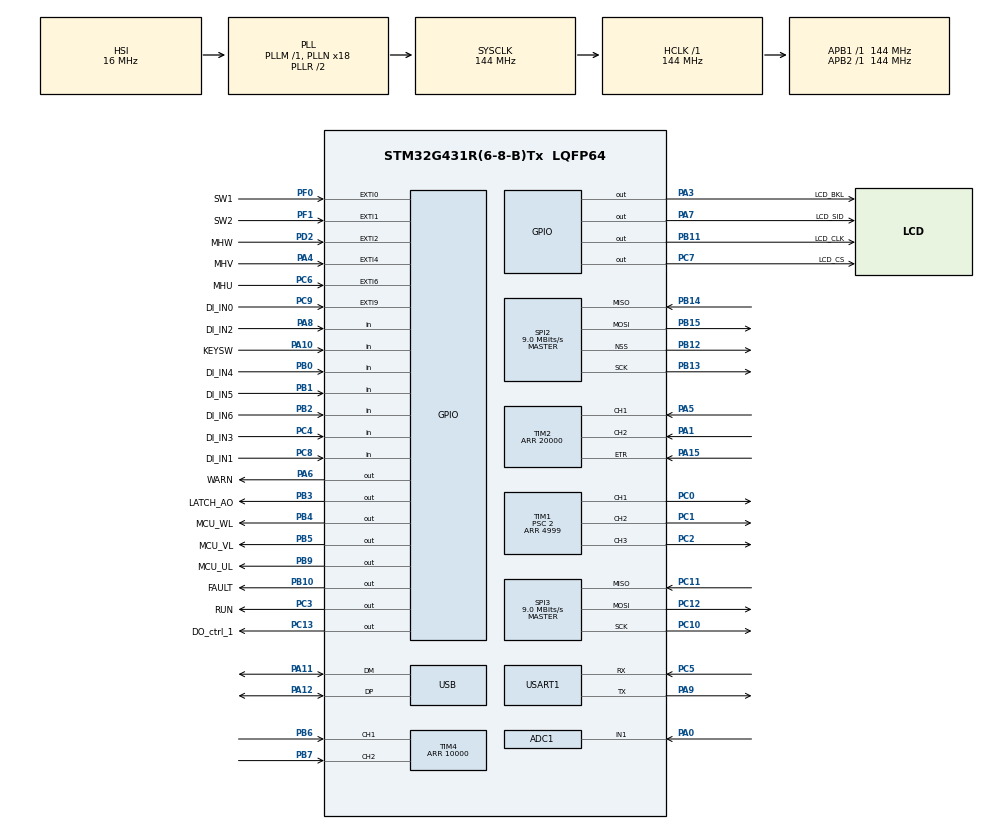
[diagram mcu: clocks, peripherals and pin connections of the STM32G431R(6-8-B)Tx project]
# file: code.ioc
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ADC1.Channel-1\#ChannelRegularConversion=ADC_CHANNEL_1
ADC1.ContinuousConvMode=ENABLE
ADC1.DMAContinuousRequests=ENABLE
ADC1.NbrOfConversionFlag=1
ADC1.OffsetNumber-1\#ChannelRegularConversion=ADC_OFFSET_NONE
ADC1.Rank-1\#ChannelRegularConversion=1
ADC1.SamplingTime-1\#ChannelRegularConversion=ADC_SAMPLETIME_247CYCLES_5
ADC1.master=1
Dma.ADC1.0.Direction=DMA_PERIPH_TO_MEMORY
Dma.ADC1.0.EventEnable=DISABLE
Dma.ADC1.0.Instance=DMA1_Channel1
Dma.ADC1.0.MemDataAlignment=DMA_MDATAALIGN_HALFWORD
Dma.ADC1.0.MemInc=DMA_MINC_ENABLE
Dma.ADC1.0.Mode=DMA_NORMAL
Dma.ADC1.0.PeriphDataAlignment=DMA_PDATAALIGN_HALFWORD
Dma.ADC1.0.PeriphInc=DMA_PINC_DISABLE
Dma.ADC1.0.Polarity=HAL_DMAMUX_REQ_GEN_RISING
Dma.ADC1.0.Priority=DMA_PRIORITY_LOW
Dma.ADC1.0.RequestNumber=1
Dma.ADC1.0.SignalID=NONE
Dma.ADC1.0.SyncEnable=DISABLE
Dma.ADC1.0.SyncPolarity=HAL_DMAMUX_SYNC_NO_EVENT
Dma.ADC1.0.SyncRequestNumber=1
Dma.ADC1.0.SyncSignalID=NONE
Dma.Request0=ADC1
Dma.Request1=USART1_RX
Dma.USART1_RX.1.Direction=DMA_PERIPH_TO_MEMORY
Dma.USART1_RX.1.EventEnable=DISABLE
Dma.USART1_RX.1.Instance=DMA1_Channel2
Dma.USART1_RX.1.MemDataAlignment=DMA_MDATAALIGN_BYTE
Dma.USART1_RX.1.MemInc=DMA_MINC_ENABLE
Dma.USART1_RX.1.Mode=DMA_NORMAL
Dma.USART1_RX.1.PeriphDataAlignment=DMA_PDATAALIGN_BYTE
Dma.USART1_RX.1.PeriphInc=DMA_PINC_DISABLE
Dma.USART1_RX.1.Polarity=HAL_DMAMUX_REQ_GEN_RISING
Dma.USART1_RX.1.Priority=DMA_PRIORITY_LOW
Dma.USART1_RX.1.RequestNumber=1
Dma.USART1_RX.1.SignalID=NONE
Dma.USART1_RX.1.SyncEnable=DISABLE
Dma.USART1_RX.1.SyncPolarity=HAL_DMAMUX_SYNC_NO_EVENT
Dma.USART1_RX.1.SyncRequestNumber=1
Dma.USART1_RX.1.SyncSignalID=NONE
Mcu.Family=STM32G4
Mcu.Name=STM32G431R(6-8-B)Tx
Mcu.Package=LQFP64
NVIC.DMA1_Channel1_IRQn=true\:0\:0\:false\:false\:true\:false\:true\:true
NVIC.DMA1_Channel2_IRQn=true\:0\:0\:false\:false\:true\:false\:true\:true
NVIC.EXTI2_IRQn=true\:0\:0\:false\:false\:true\:true\:true\:true
NVIC.EXTI4_IRQn=true\:0\:0\:false\:false\:true\:true\:true\:true
NVIC.EXTI9_5_IRQn=true\:0\:0\:false\:false\:true\:true\:true\:true
NVIC.PriorityGroup=NVIC_PRIORITYGROUP_4
NVIC.TIM2_IRQn=true\:0\:0\:false\:false\:true\:true\:true\:true
NVIC.TIM4_IRQn=true\:0\:0\:false\:false\:true\:true\:true\:true
NVIC.TIM6_DAC_IRQn=true\:10\:0\:true\:false\:true\:true\:true\:true
NVIC.USART1_IRQn=true\:0\:0\:false\:false\:true\:true\:true\:true
PA0.Mode=IN1-Single-Ended
PA0.Signal=ADC1_IN1
PA1.Signal=S_TIM2_CH2
PA10.GPIO_Label=KEYSW
PA10.Signal=GPIO_Input
PA11.Mode=Device
PA11.Signal=USB_DM
PA12.Mode=Device
PA12.Signal=USB_DP
PA13.Mode=Serial_Wire
PA13.Signal=SYS_JTMS-SWDIO
PA14.Mode=Serial_Wire
PA14.Signal=SYS_JTCK-SWCLK
PA15.Signal=S_TIM2_ETR
PA2.Signal=ADC1_IN3
PA3.GPIO_Label=LCD_BKL
PA3.GPIO_PuPd=GPIO_PULLDOWN
PA3.Signal=GPIO_Output
PA4.GPIO_Label=MHV
PA4.GPIO_ModeDefaultEXTI=GPIO_MODE_IT_RISING_FALLING
PA4.GPIO_PuPd=GPIO_PULLUP
PA4.Signal=GPXTI4
PA5.Signal=S_TIM2_CH1
PA6.GPIO_Label=WARN
PA6.GPIO_PuPd=GPIO_PULLDOWN
PA6.Signal=GPIO_Output
PA7.GPIO_Label=LCD_SID
PA7.GPIO_PuPd=GPIO_PULLUP
PA7.Signal=GPIO_Output
PA8.GPIO_Label=DI_IN2
PA8.Signal=GPIO_Input
PA9.Mode=Asynchronous
PA9.Signal=USART1_TX
PB0.GPIO_Label=DI_IN4
PB0.Signal=GPIO_Input
PB1.GPIO_Label=DI_IN5
PB1.Signal=GPIO_Input
PB10.GPIO_Label=FAULT
PB10.GPIO_PuPd=GPIO_PULLDOWN
PB10.Signal=GPIO_Output
PB11.GPIO_Label=LCD_CLK
PB11.GPIO_PuPd=GPIO_PULLUP
PB11.Signal=GPIO_Output
PB12.Mode=NSS_Signal_Hard_Output
PB12.Signal=SPI2_NSS
PB13.Mode=Full_Duplex_Master
PB13.Signal=SPI2_SCK
PB14.Mode=Full_Duplex_Master
PB14.Signal=SPI2_MISO
PB15.Mode=Full_Duplex_Master
PB15.Signal=SPI2_MOSI
PB2.GPIO_Label=DI_IN6
PB2.Signal=GPIO_Input
PB3.GPIO_Label=LATCH_AO
PB3.Signal=GPIO_Output
PB4.GPIO_Label=MCU_WL
PB4.GPIO_PuPd=GPIO_PULLDOWN
PB4.GPIO_Speed=GPIO_SPEED_FREQ_MEDIUM
PB4.Signal=GPIO_Output
PB5.GPIO_Label=MCU_VL
PB5.GPIO_PuPd=GPIO_PULLDOWN
PB5.GPIO_Speed=GPIO_SPEED_FREQ_MEDIUM
PB5.Signal=GPIO_Output
PB6.Signal=S_TIM4_CH1
PB7.Signal=S_TIM4_CH2
PB9.GPIO_Label=MCU_UL
PB9.GPIO_PuPd=GPIO_PULLDOWN
PB9.GPIO_Speed=GPIO_SPEED_FREQ_MEDIUM
PB9.Signal=GPIO_Output
PC0.Signal=S_TIM1_CH1
PC1.Signal=S_TIM1_CH2
PC10.Mode=Full_Duplex_Master
PC10.Signal=SPI3_SCK
PC11.Mode=Full_Duplex_Master
PC11.Signal=SPI3_MISO
PC12.Mode=Full_Duplex_Master
PC12.Signal=SPI3_MOSI
PC13.GPIO_Label=DO_ctrl_1
PC13.GPIO_PuPd=GPIO_PULLUP
PC13.PinState=GPIO_PIN_SET
PC13.Signal=GPIO_Output
PC14-OSC32_IN.Mode=LSE-External-Oscillator
PC14-OSC32_IN.Signal=RCC_OSC32_IN
PC15-OSC32_OUT.Mode=LSE-External-Oscillator
PC15-OSC32_OUT.Signal=RCC_OSC32_OUT
PC2.Signal=S_TIM1_CH3
PC3.GPIO_Label=RUN
PC3.GPIO_PuPd=GPIO_PULLDOWN
PC3.Signal=GPIO_Output
PC4.GPIO_Label=DI_IN3
PC4.Signal=GPIO_Input
PC5.Mode=Asynchronous
PC5.Signal=USART1_RX
PC6.GPIO_Label=MHU
PC6.GPIO_ModeDefaultEXTI=GPIO_MODE_IT_RISING_FALLING
PC6.GPIO_PuPd=GPIO_PULLUP
PC6.Signal=GPXTI6
PC7.GPIO_Label=LCD_CS
PC7.GPIO_PuPd=GPIO_PULLUP
PC7.Signal=GPIO_Output
PC8.GPIO_Label=DI_IN1
PC8.Signal=GPIO_Input
PC9.GPIO_Label=DI_IN0
PC9.GPIO_ModeDefaultEXTI=GPIO_MODE_IT_FALLING
PC9.Signal=GPXTI9
PD2.GPIO_Label=MHW
PD2.GPIO_ModeDefaultEXTI=GPIO_MODE_IT_RISING_FALLING
PD2.GPIO_PuPd=GPIO_PULLUP
PD2.Signal=GPXTI2
PF0-OSC_IN.GPIO_Label=SW1
PF0-OSC_IN.GPIO_ModeDefaultEXTI=GPIO_MODE_IT_FALLING
PF0-OSC_IN.Signal=GPXTI0
PF1-OSC_OUT.GPIO_Label=SW2
PF1-OSC_OUT.GPIO_ModeDefaultEXTI=GPIO_MODE_IT_FALLING
PF1-OSC_OUT.Signal=GPXTI1
ProjectManager.HeapSize=0x200
ProjectManager.StackSize=0x400
ProjectManager.TargetToolchain=MDK-ARM V5.32
RCC.ADC12Freq_Value=144000000
RCC.AHBFreq_Value=144000000
RCC.APB1Freq_Value=144000000
RCC.APB1TimFreq_Value=144000000
RCC.APB2Freq_Value=144000000
RCC.APB2TimFreq_Value=144000000
RCC.CortexFreq_Value=144000000
RCC.EXTERNAL_CLOCK_VALUE=12288000
RCC.HCLKFreq_Value=144000000
RCC.HSE_VALUE=8000000
RCC.HSI48_VALUE=48000000
RCC.HSI_VALUE=16000000
RCC.PLLN=18
RCC.PLLQ=RCC_PLLQ_DIV6
RCC.SYSCLKFreq_VALUE=144000000
RCC.SYSCLKSource=RCC_SYSCLKSOURCE_PLLCLK
RCC.USBFreq_Value=48000000
RCC.VCOOutputFreq_Value=288000000
SH.S_TIM1_CH1.0=TIM1_CH1,PWM Generation1 CH1
SH.S_TIM1_CH2.0=TIM1_CH2,PWM Generation2 CH2
SH.S_TIM1_CH3.0=TIM1_CH3,PWM Generation3 CH3
SH.S_TIM2_CH1.0=TIM2_CH1,Encoder_Interface_w_index
SH.S_TIM2_CH2.0=TIM2_CH2,Encoder_Interface_w_index
SH.S_TIM2_ETR.0=TIM2_ETR,Encoder_Interface_w_index
SH.S_TIM4_CH1.0=TIM4_CH1,Encoder_Interface
SH.S_TIM4_CH2.0=TIM4_CH2,Encoder_Interface
SPI2.BaudRatePrescaler=SPI_BAUDRATEPRESCALER_16
SPI2.CalculateBaudRate=9.0 MBits/s
SPI2.DataSize=SPI_DATASIZE_8BIT
SPI2.Direction=SPI_DIRECTION_2LINES
SPI2.Mode=SPI_MODE_MASTER
SPI2.VirtualNSS=VM_NSSHARD
SPI2.VirtualType=VM_MASTER
SPI3.BaudRatePrescaler=SPI_BAUDRATEPRESCALER_16
SPI3.CalculateBaudRate=9.0 MBits/s
SPI3.DataSize=SPI_DATASIZE_8BIT
SPI3.Direction=SPI_DIRECTION_2LINES
SPI3.Mode=SPI_MODE_MASTER
SPI3.VirtualType=VM_MASTER
TIM1.Channel-PWM\ Generation1\ CH1=TIM_CHANNEL_1
TIM1.Channel-PWM\ Generation2\ CH2=TIM_CHANNEL_2
TIM1.Channel-PWM\ Generation3\ CH3=TIM_CHANNEL_3
TIM1.PeriodNoDither=4999
TIM1.Prescaler=2
TIM2.ClockDivision=TIM_CLOCKDIVISION_DIV1
TIM2.EncoderMode=TIM_ENCODERMODE_TI12
TIM2.IC1Filter=6
TIM2.IndexFilter=6
TIM2.PeriodNoDither=20000
TIM4.ClockDivision=TIM_CLOCKDIVISION_DIV1
TIM4.CounterMode=TIM_COUNTERMODE_UP
TIM4.EncoderMode=TIM_ENCODERMODE_TI12
TIM4.IC1Filter=6
TIM4.IC2Filter=6
TIM4.PeriodNoDither=10000
TIM6.AutoReloadPreload=TIM_AUTORELOAD_PRELOAD_ENABLE
TIM6.PeriodNoDither=9999
TIM6.Prescaler=1439
USART1.VirtualMode-Asynchronous=VM_ASYNC
VP_RTC_VS_RTC_Activate.Mode=RTC_Enabled
VP_RTC_VS_RTC_WakeUp_intern.Mode=WakeUp
VP_SYS_VS_DBSignals.Mode=DisableDeadBatterySignals
VP_TIM6_VS_ClockSourceINT.Mode=Enable_Timer
board=custom

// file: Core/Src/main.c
/* USER CODE BEGIN Header */
/**
  ******************************************************************************
  * @file           : main.c
  * @brief          : Main program body
  ******************************************************************************
  * @attention
  *
  * Copyright (c) 2024 STMicroelectronics.
  * All rights reserved.
  *
  * This software is licensed under terms that can be found in the LICENSE file
  * in the root directory of this software component.
  * If no LICENSE file comes with this software, it is provided AS-IS.
  *
  ******************************************************************************
  */
/* USER CODE END Header */
#include "main.h"

/* USER CODE BEGIN Includes */
#include "app.h"

/* USER CODE END Includes */

ADC_HandleTypeDef hadc1;
DMA_HandleTypeDef hdma_adc1;

RTC_HandleTypeDef hrtc;

SPI_HandleTypeDef hspi2;
SPI_HandleTypeDef hspi3;

TIM_HandleTypeDef htim1;
TIM_HandleTypeDef htim2;
TIM_HandleTypeDef htim4;
TIM_HandleTypeDef htim6;

UART_HandleTypeDef huart1;
DMA_HandleTypeDef hdma_usart1_rx;

PCD_HandleTypeDef hpcd_USB_FS;

void SystemClock_Config(void);
static void MX_GPIO_Init(void);
static void MX_DMA_Init(void);
static void MX_SPI2_Init(void);
static void MX_SPI3_Init(void);
static void MX_TIM1_Init(void);
static void MX_TIM2_Init(void);
static void MX_TIM4_Init(void);
static void MX_ADC1_Init(void);
static void MX_USART1_UART_Init(void);
static void MX_USB_PCD_Init(void);
static void MX_RTC_Init(void);
static void MX_TIM6_Init(void);

int main(void)
{

  /* MCU Configuration--------------------------------------------------------*/

  /* Reset of all peripherals, Initializes the Flash interface and the Systick. */
  HAL_Init();

  /* Configure the system clock */
  SystemClock_Config();

  /* Initialize all configured peripherals */
  MX_GPIO_Init();
  MX_DMA_Init();
  MX_SPI2_Init();
  MX_SPI3_Init();
  MX_TIM1_Init();
  MX_TIM2_Init();
  MX_TIM4_Init();
  MX_ADC1_Init();
  MX_USART1_UART_Init();
  MX_USB_PCD_Init();
  MX_RTC_Init();
  MX_TIM6_Init();
  /* USER CODE BEGIN 2 */
  app_init();

  /* USER CODE END 2 */

  /* Infinite loop */
  /* USER CODE BEGIN WHILE */
  while (1)
  {
  app_proc();
    /* USER CODE END WHILE */

  }
}

void SystemClock_Config(void)
{
  RCC_OscInitTypeDef RCC_OscInitStruct = {0};
  RCC_ClkInitTypeDef RCC_ClkInitStruct = {0};

  /** Configure the main internal regulator output voltage
  */
  HAL_PWREx_ControlVoltageScaling(PWR_REGULATOR_VOLTAGE_SCALE1);

  /** Initializes the RCC Oscillators according to the specified parameters
  * in the RCC_OscInitTypeDef structure.
  */
  RCC_OscInitStruct.OscillatorType = RCC_OSCILLATORTYPE_HSI|RCC_OSCILLATORTYPE_LSI;
  RCC_OscInitStruct.HSIState = RCC_HSI_ON;
  RCC_OscInitStruct.HSICalibrationValue = RCC_HSICALIBRATION_DEFAULT;
  RCC_OscInitStruct.LSIState = RCC_LSI_ON;
  RCC_OscInitStruct.PLL.PLLState = RCC_PLL_ON;
  RCC_OscInitStruct.PLL.PLLSource = RCC_PLLSOURCE_HSI;
  RCC_OscInitStruct.PLL.PLLM = RCC_PLLM_DIV1;
  RCC_OscInitStruct.PLL.PLLN = 18;
  RCC_OscInitStruct.PLL.PLLP = RCC_PLLP_DIV2;
  RCC_OscInitStruct.PLL.PLLQ = RCC_PLLQ_DIV6;
  RCC_OscInitStruct.PLL.PLLR = RCC_PLLR_DIV2;
  if (HAL_RCC_OscConfig(&RCC_OscInitStruct) != HAL_OK)
  {
    Error_Handler();
  }

  /** Initializes the CPU, AHB and APB buses clocks
  */
  RCC_ClkInitStruct.ClockType = RCC_CLOCKTYPE_HCLK|RCC_CLOCKTYPE_SYSCLK
                              |RCC_CLOCKTYPE_PCLK1|RCC_CLOCKTYPE_PCLK2;
  RCC_ClkInitStruct.SYSCLKSource = RCC_SYSCLKSOURCE_PLLCLK;
  RCC_ClkInitStruct.AHBCLKDivider = RCC_SYSCLK_DIV1;
  RCC_ClkInitStruct.APB1CLKDivider = RCC_HCLK_DIV1;
  RCC_ClkInitStruct.APB2CLKDivider = RCC_HCLK_DIV1;

  if (HAL_RCC_ClockConfig(&RCC_ClkInitStruct, FLASH_LATENCY_4) != HAL_OK)
  {
    Error_Handler();
  }
}

static void MX_ADC1_Init(void)
{

  ADC_MultiModeTypeDef multimode = {0};
  ADC_ChannelConfTypeDef sConfig = {0};

  /** Common config
  */
  hadc1.Instance = ADC1;
  hadc1.Init.ClockPrescaler = ADC_CLOCK_SYNC_PCLK_DIV4;
  hadc1.Init.Resolution = ADC_RESOLUTION_12B;
  hadc1.Init.DataAlign = ADC_DATAALIGN_RIGHT;
  hadc1.Init.GainCompensation = 0;
  hadc1.Init.ScanConvMode = ADC_SCAN_DISABLE;
  hadc1.Init.EOCSelection = ADC_EOC_SINGLE_CONV;
  hadc1.Init.LowPowerAutoWait = DISABLE;
  hadc1.Init.ContinuousConvMode = ENABLE;
  hadc1.Init.NbrOfConversion = 1;
  hadc1.Init.DiscontinuousConvMode = DISABLE;
  hadc1.Init.ExternalTrigConv = ADC_SOFTWARE_START;
  hadc1.Init.ExternalTrigConvEdge = ADC_EXTERNALTRIGCONVEDGE_NONE;
  hadc1.Init.DMAContinuousRequests = ENABLE;
  hadc1.Init.Overrun = ADC_OVR_DATA_PRESERVED;
  hadc1.Init.OversamplingMode = DISABLE;
  if (HAL_ADC_Init(&hadc1) != HAL_OK)
  {
    Error_Handler();
  }

  /** Configure the ADC multi-mode
  */
  multimode.Mode = ADC_MODE_INDEPENDENT;
  if (HAL_ADCEx_MultiModeConfigChannel(&hadc1, &multimode) != HAL_OK)
  {
    Error_Handler();
  }

  /** Configure Regular Channel
  */
  sConfig.Channel = ADC_CHANNEL_1;
  sConfig.Rank = ADC_REGULAR_RANK_1;
  sConfig.SamplingTime = ADC_SAMPLETIME_247CYCLES_5;
  sConfig.SingleDiff = ADC_SINGLE_ENDED;
  sConfig.OffsetNumber = ADC_OFFSET_NONE;
  sConfig.Offset = 0;
  if (HAL_ADC_ConfigChannel(&hadc1, &sConfig) != HAL_OK)
  {
    Error_Handler();
  }

}

static void MX_RTC_Init(void)
{

  /** Initialize RTC Only
  */
  hrtc.Instance = RTC;
  hrtc.Init.HourFormat = RTC_HOURFORMAT_24;
  hrtc.Init.AsynchPrediv = 127;
  hrtc.Init.SynchPrediv = 255;
  hrtc.Init.OutPut = RTC_OUTPUT_DISABLE;
  hrtc.Init.OutPutRemap = RTC_OUTPUT_REMAP_NONE;
  hrtc.Init.OutPutPolarity = RTC_OUTPUT_POLARITY_HIGH;
  hrtc.Init.OutPutType = RTC_OUTPUT_TYPE_OPENDRAIN;
  hrtc.Init.OutPutPullUp = RTC_OUTPUT_PULLUP_NONE;
  if (HAL_RTC_Init(&hrtc) != HAL_OK)
  {
    Error_Handler();
  }

  /** Enable the WakeUp
  */
  if (HAL_RTCEx_SetWakeUpTimer(&hrtc, 0, RTC_WAKEUPCLOCK_RTCCLK_DIV16) != HAL_OK)
  {
    Error_Handler();
  }

}

static void MX_SPI2_Init(void)
{

  /* SPI2 parameter configuration*/
  hspi2.Instance = SPI2;
  hspi2.Init.Mode = SPI_MODE_MASTER;
  hspi2.Init.Direction = SPI_DIRECTION_2LINES;
  hspi2.Init.DataSize = SPI_DATASIZE_8BIT;
  hspi2.Init.CLKPolarity = SPI_POLARITY_LOW;
  hspi2.Init.CLKPhase = SPI_PHASE_1EDGE;
  hspi2.Init.NSS = SPI_NSS_HARD_OUTPUT;
  hspi2.Init.BaudRatePrescaler = SPI_BAUDRATEPRESCALER_16;
  hspi2.Init.FirstBit = SPI_FIRSTBIT_MSB;
  hspi2.Init.TIMode = SPI_TIMODE_DISABLE;
  hspi2.Init.CRCCalculation = SPI_CRCCALCULATION_DISABLE;
  hspi2.Init.CRCPolynomial = 7;
  hspi2.Init.CRCLength = SPI_CRC_LENGTH_DATASIZE;
  hspi2.Init.NSSPMode = SPI_NSS_PULSE_ENABLE;
  if (HAL_SPI_Init(&hspi2) != HAL_OK)
  {
    Error_Handler();
  }

}

static void MX_SPI3_Init(void)
{

  /* SPI3 parameter configuration*/
  hspi3.Instance = SPI3;
  hspi3.Init.Mode = SPI_MODE_MASTER;
  hspi3.Init.Direction = SPI_DIRECTION_2LINES;
  hspi3.Init.DataSize = SPI_DATASIZE_8BIT;
  hspi3.Init.CLKPolarity = SPI_POLARITY_LOW;
  hspi3.Init.CLKPhase = SPI_PHASE_1EDGE;
  hspi3.Init.NSS = SPI_NSS_SOFT;
  hspi3.Init.BaudRatePrescaler = SPI_BAUDRATEPRESCALER_16;
  hspi3.Init.FirstBit = SPI_FIRSTBIT_MSB;
  hspi3.Init.TIMode = SPI_TIMODE_DISABLE;
  hspi3.Init.CRCCalculation = SPI_CRCCALCULATION_DISABLE;
  hspi3.Init.CRCPolynomial = 7;
  hspi3.Init.CRCLength = SPI_CRC_LENGTH_DATASIZE;
  hspi3.Init.NSSPMode = SPI_NSS_PULSE_ENABLE;
  if (HAL_SPI_Init(&hspi3) != HAL_OK)
  {
    Error_Handler();
  }

}

static void MX_TIM1_Init(void)
{

  TIM_MasterConfigTypeDef sMasterConfig = {0};
  TIM_OC_InitTypeDef sConfigOC = {0};
  TIM_BreakDeadTimeConfigTypeDef sBreakDeadTimeConfig = {0};

  htim1.Instance = TIM1;
  htim1.Init.Prescaler = 2;
  htim1.Init.CounterMode = TIM_COUNTERMODE_UP;
  htim1.Init.Period = 4999;
  htim1.Init.ClockDivision = TIM_CLOCKDIVISION_DIV1;
  htim1.Init.RepetitionCounter = 0;
  htim1.Init.AutoReloadPreload = TIM_AUTORELOAD_PRELOAD_DISABLE;
  if (HAL_TIM_PWM_Init(&htim1) != HAL_OK)
  {
    Error_Handler();
  }
  sMasterConfig.MasterOutputTrigger = TIM_TRGO_RESET;
  sMasterConfig.MasterOutputTrigger2 = TIM_TRGO2_RESET;
  sMasterConfig.MasterSlaveMode = TIM_MASTERSLAVEMODE_DISABLE;
  if (HAL_TIMEx_MasterConfigSynchronization(&htim1, &sMasterConfig) != HAL_OK)
  {
    Error_Handler();
  }
  sConfigOC.OCMode = TIM_OCMODE_PWM1;
  sConfigOC.Pulse = 0;
  sConfigOC.OCPolarity = TIM_OCPOLARITY_HIGH;
  sConfigOC.OCNPolarity = TIM_OCNPOLARITY_HIGH;
  sConfigOC.OCFastMode = TIM_OCFAST_DISABLE;
  sConfigOC.OCIdleState = TIM_OCIDLESTATE_RESET;
  sConfigOC.OCNIdleState = TIM_OCNIDLESTATE_RESET;
  if (HAL_TIM_PWM_ConfigChannel(&htim1, &sConfigOC, TIM_CHANNEL_1) != HAL_OK)
  {
    Error_Handler();
  }
  if (HAL_TIM_PWM_ConfigChannel(&htim1, &sConfigOC, TIM_CHANNEL_2) != HAL_OK)
  {
    Error_Handler();
  }
  if (HAL_TIM_PWM_ConfigChannel(&htim1, &sConfigOC, TIM_CHANNEL_3) != HAL_OK)
  {
    Error_Handler();
  }
  sBreakDeadTimeConfig.OffStateRunMode = TIM_OSSR_DISABLE;
  sBreakDeadTimeConfig.OffStateIDLEMode = TIM_OSSI_DISABLE;
  sBreakDeadTimeConfig.LockLevel = TIM_LOCKLEVEL_OFF;
  sBreakDeadTimeConfig.DeadTime = 0;
  sBreakDeadTimeConfig.BreakState = TIM_BREAK_DISABLE;
  sBreakDeadTimeConfig.BreakPolarity = TIM_BREAKPOLARITY_HIGH;
  sBreakDeadTimeConfig.BreakFilter = 0;
  sBreakDeadTimeConfig.BreakAFMode = TIM_BREAK_AFMODE_INPUT;
  sBreakDeadTimeConfig.Break2State = TIM_BREAK2_DISABLE;
  sBreakDeadTimeConfig.Break2Polarity = TIM_BREAK2POLARITY_HIGH;
  sBreakDeadTimeConfig.Break2Filter = 0;
  sBreakDeadTimeConfig.Break2AFMode = TIM_BREAK_AFMODE_INPUT;
  sBreakDeadTimeConfig.AutomaticOutput = TIM_AUTOMATICOUTPUT_DISABLE;
  if (HAL_TIMEx_ConfigBreakDeadTime(&htim1, &sBreakDeadTimeConfig) != HAL_OK)
  {
    Error_Handler();
  }
  HAL_TIM_MspPostInit(&htim1);

}

static void MX_TIM2_Init(void)
{

  TIM_Encoder_InitTypeDef sConfig = {0};
  TIM_MasterConfigTypeDef sMasterConfig = {0};
  TIMEx_EncoderIndexConfigTypeDef sEncoderIndexConfig = {0};

  htim2.Instance = TIM2;
  htim2.Init.Prescaler = 0;
  htim2.Init.CounterMode = TIM_COUNTERMODE_UP;
  htim2.Init.Period = 20000;
  htim2.Init.ClockDivision = TIM_CLOCKDIVISION_DIV1;
  htim2.Init.AutoReloadPreload = TIM_AUTORELOAD_PRELOAD_DISABLE;
  sConfig.EncoderMode = TIM_ENCODERMODE_TI12;
  sConfig.IC1Polarity = TIM_ICPOLARITY_RISING;
  sConfig.IC1Selection = TIM_ICSELECTION_DIRECTTI;
  sConfig.IC1Prescaler = TIM_ICPSC_DIV1;
  sConfig.IC1Filter = 6;
  sConfig.IC2Polarity = TIM_ICPOLARITY_RISING;
  sConfig.IC2Selection = TIM_ICSELECTION_DIRECTTI;
  sConfig.IC2Prescaler = TIM_ICPSC_DIV1;
  sConfig.IC2Filter = 0;
  if (HAL_TIM_Encoder_Init(&htim2, &sConfig) != HAL_OK)
  {
    Error_Handler();
  }
  sMasterConfig.MasterOutputTrigger = TIM_TRGO_RESET;
  sMasterConfig.MasterSlaveMode = TIM_MASTERSLAVEMODE_DISABLE;
  if (HAL_TIMEx_MasterConfigSynchronization(&htim2, &sMasterConfig) != HAL_OK)
  {
    Error_Handler();
  }
  sEncoderIndexConfig.Polarity = TIM_ENCODERINDEX_POLARITY_NONINVERTED;
  sEncoderIndexConfig.Prescaler = TIM_ENCODERINDEX_PRESCALER_DIV1;
  sEncoderIndexConfig.Filter = 6;
  sEncoderIndexConfig.FirstIndexEnable = DISABLE;
  sEncoderIndexConfig.Position = TIM_ENCODERINDEX_POSITION_00;
  sEncoderIndexConfig.Direction = TIM_ENCODERINDEX_DIRECTION_UP_DOWN;
  if (HAL_TIMEx_ConfigEncoderIndex(&htim2, &sEncoderIndexConfig) != HAL_OK)
  {
    Error_Handler();
  }

}

static void MX_TIM4_Init(void)
{

  TIM_Encoder_InitTypeDef sConfig = {0};
  TIM_MasterConfigTypeDef sMasterConfig = {0};

  htim4.Instance = TIM4;
  htim4.Init.Prescaler = 0;
  htim4.Init.CounterMode = TIM_COUNTERMODE_UP;
  htim4.Init.Period = 10000;
  htim4.Init.ClockDivision = TIM_CLOCKDIVISION_DIV1;
  htim4.Init.AutoReloadPreload = TIM_AUTORELOAD_PRELOAD_DISABLE;
  sConfig.EncoderMode = TIM_ENCODERMODE_TI12;
  sConfig.IC1Polarity = TIM_ICPOLARITY_RISING;
  sConfig.IC1Selection = TIM_ICSELECTION_DIRECTTI;
  sConfig.IC1Prescaler = TIM_ICPSC_DIV1;
  sConfig.IC1Filter = 16;
  sConfig.IC2Polarity = TIM_ICPOLARITY_RISING;
  sConfig.IC2Selection = TIM_ICSELECTION_DIRECTTI;
  sConfig.IC2Prescaler = TIM_ICPSC_DIV1;
  sConfig.IC2Filter = 16;
  if (HAL_TIM_Encoder_Init(&htim4, &sConfig) != HAL_OK)
  {
    Error_Handler();
  }
  sMasterConfig.MasterOutputTrigger = TIM_TRGO_RESET;
  sMasterConfig.MasterSlaveMode = TIM_MASTERSLAVEMODE_DISABLE;
  if (HAL_TIMEx_MasterConfigSynchronization(&htim4, &sMasterConfig) != HAL_OK)
  {
    Error_Handler();
  }

}

static void MX_TIM6_Init(void)
{

  TIM_MasterConfigTypeDef sMasterConfig = {0};

  htim6.Instance = TIM6;
  htim6.Init.Prescaler = 1439;
  htim6.Init.CounterMode = TIM_COUNTERMODE_UP;
  htim6.Init.Period = 9999;
  htim6.Init.AutoReloadPreload = TIM_AUTORELOAD_PRELOAD_ENABLE;
  if (HAL_TIM_Base_Init(&htim6) != HAL_OK)
  {
    Error_Handler();
  }
  sMasterConfig.MasterOutputTrigger = TIM_TRGO_RESET;
  sMasterConfig.MasterSlaveMode = TIM_MASTERSLAVEMODE_DISABLE;
  if (HAL_TIMEx_MasterConfigSynchronization(&htim6, &sMasterConfig) != HAL_OK)
  {
    Error_Handler();
  }

}

static void MX_USART1_UART_Init(void)
{

  huart1.Instance = USART1;
  huart1.Init.BaudRate = 115200;
  huart1.Init.WordLength = UART_WORDLENGTH_8B;
  huart1.Init.StopBits = UART_STOPBITS_1;
  huart1.Init.Parity = UART_PARITY_NONE;
  huart1.Init.Mode = UART_MODE_TX_RX;
  huart1.Init.HwFlowCtl = UART_HWCONTROL_NONE;
  huart1.Init.OverSampling = UART_OVERSAMPLING_16;
  huart1.Init.OneBitSampling = UART_ONE_BIT_SAMPLE_DISABLE;
  huart1.Init.ClockPrescaler = UART_PRESCALER_DIV1;
  huart1.AdvancedInit.AdvFeatureInit = UART_ADVFEATURE_NO_INIT;
  if (HAL_UART_Init(&huart1) != HAL_OK)
  {
    Error_Handler();
  }
  if (HAL_UARTEx_SetTxFifoThreshold(&huart1, UART_TXFIFO_THRESHOLD_1_8) != HAL_OK)
  {
    Error_Handler();
  }
  if (HAL_UARTEx_SetRxFifoThreshold(&huart1, UART_RXFIFO_THRESHOLD_1_8) != HAL_OK)
  {
    Error_Handler();
  }
  if (HAL_UARTEx_DisableFifoMode(&huart1) != HAL_OK)
  {
    Error_Handler();
  }

}

static void MX_USB_PCD_Init(void)
{

  hpcd_USB_FS.Instance = USB;
  hpcd_USB_FS.Init.dev_endpoints = 8;
  hpcd_USB_FS.Init.speed = PCD_SPEED_FULL;
  hpcd_USB_FS.Init.phy_itface = PCD_PHY_EMBEDDED;
  hpcd_USB_FS.Init.Sof_enable = DISABLE;
  hpcd_USB_FS.Init.low_power_enable = DISABLE;
  hpcd_USB_FS.Init.lpm_enable = DISABLE;
  hpcd_USB_FS.Init.battery_charging_enable = DISABLE;
  if (HAL_PCD_Init(&hpcd_USB_FS) != HAL_OK)
  {
    Error_Handler();
  }

}

static void MX_DMA_Init(void)
{

  /* DMA controller clock enable */
  __HAL_RCC_DMAMUX1_CLK_ENABLE();
  __HAL_RCC_DMA1_CLK_ENABLE();

  /* DMA interrupt init */
  /* DMA1_Channel1_IRQn interrupt configuration */
  HAL_NVIC_SetPriority(DMA1_Channel1_IRQn, 0, 0);
  HAL_NVIC_EnableIRQ(DMA1_Channel1_IRQn);
  /* DMA1_Channel2_IRQn interrupt configuration */
  HAL_NVIC_SetPriority(DMA1_Channel2_IRQn, 0, 0);
  HAL_NVIC_EnableIRQ(DMA1_Channel2_IRQn);

}

static void MX_GPIO_Init(void)
{
  GPIO_InitTypeDef GPIO_InitStruct = {0};

  /* GPIO Ports Clock Enable */
  __HAL_RCC_GPIOC_CLK_ENABLE();
  __HAL_RCC_GPIOF_CLK_ENABLE();
  __HAL_RCC_GPIOA_CLK_ENABLE();
  __HAL_RCC_GPIOB_CLK_ENABLE();
  __HAL_RCC_GPIOD_CLK_ENABLE();

  /*Configure GPIO pin Output Level */
  HAL_GPIO_WritePin(DO_ctrl_1_GPIO_Port, DO_ctrl_1_Pin, GPIO_PIN_SET);

  /*Configure GPIO pin Output Level */
  HAL_GPIO_WritePin(GPIOC, RUN_Pin|LCD_CS_Pin, GPIO_PIN_RESET);

  /*Configure GPIO pin Output Level */
  HAL_GPIO_WritePin(DO_ctrl_0_GPIO_Port, DO_ctrl_0_Pin, GPIO_PIN_SET);

  /*Configure GPIO pin Output Level */
  HAL_GPIO_WritePin(GPIOA, LCD_BKL_Pin|WARN_Pin|LCD_SID_Pin, GPIO_PIN_RESET);

  /*Configure GPIO pin Output Level */
  HAL_GPIO_WritePin(GPIOB, FAULT_Pin|LCD_CLK_Pin|LATCH_AO_Pin|MCU_WL_Pin
                          |MCU_VL_Pin|MCU_UL_Pin, GPIO_PIN_RESET);

  /*Configure GPIO pins : DO_ctrl_1_Pin LCD_CS_Pin */
  GPIO_InitStruct.Pin = DO_ctrl_1_Pin|LCD_CS_Pin;
  GPIO_InitStruct.Mode = GPIO_MODE_OUTPUT_PP;
  GPIO_InitStruct.Pull = GPIO_PULLUP;
  GPIO_InitStruct.Speed = GPIO_SPEED_FREQ_LOW;
  HAL_GPIO_Init(GPIOC, &GPIO_InitStruct);

  /*Configure GPIO pins : SW1_Pin SW2_Pin */
  GPIO_InitStruct.Pin = SW1_Pin|SW2_Pin;
  GPIO_InitStruct.Mode = GPIO_MODE_IT_FALLING;
  GPIO_InitStruct.Pull = GPIO_NOPULL;
  HAL_GPIO_Init(GPIOF, &GPIO_InitStruct);

  /*Configure GPIO pin : RUN_Pin */
  GPIO_InitStruct.Pin = RUN_Pin;
  GPIO_InitStruct.Mode = GPIO_MODE_OUTPUT_PP;
  GPIO_InitStruct.Pull = GPIO_PULLDOWN;
  GPIO_InitStruct.Speed = GPIO_SPEED_FREQ_LOW;
  HAL_GPIO_Init(RUN_GPIO_Port, &GPIO_InitStruct);

  /*Configure GPIO pins : DO_ctrl_0_Pin LCD_SID_Pin */
  GPIO_InitStruct.Pin = DO_ctrl_0_Pin|LCD_SID_Pin;
  GPIO_InitStruct.Mode = GPIO_MODE_OUTPUT_PP;
  GPIO_InitStruct.Pull = GPIO_PULLUP;
  GPIO_InitStruct.Speed = GPIO_SPEED_FREQ_LOW;
  HAL_GPIO_Init(GPIOA, &GPIO_InitStruct);

  /*Configure GPIO pins : LCD_BKL_Pin WARN_Pin */
  GPIO_InitStruct.Pin = LCD_BKL_Pin|WARN_Pin;
  GPIO_InitStruct.Mode = GPIO_MODE_OUTPUT_PP;
  GPIO_InitStruct.Pull = GPIO_PULLDOWN;
  GPIO_InitStruct.Speed = GPIO_SPEED_FREQ_LOW;
  HAL_GPIO_Init(GPIOA, &GPIO_InitStruct);

  /*Configure GPIO pin : MHV_Pin */
  GPIO_InitStruct.Pin = MHV_Pin;
  GPIO_InitStruct.Mode = GPIO_MODE_IT_RISING_FALLING;
  GPIO_InitStruct.Pull = GPIO_PULLUP;
  HAL_GPIO_Init(MHV_GPIO_Port, &GPIO_InitStruct);

  /*Configure GPIO pins : DI_IN3_Pin DI_IN1_Pin */
  GPIO_InitStruct.Pin = DI_IN3_Pin|DI_IN1_Pin;
  GPIO_InitStruct.Mode = GPIO_MODE_INPUT;
  GPIO_InitStruct.Pull = GPIO_NOPULL;
  HAL_GPIO_Init(GPIOC, &GPIO_InitStruct);

  /*Configure GPIO pins : DI_IN4_Pin DI_IN5_Pin DI_IN6_Pin */
  GPIO_InitStruct.Pin = DI_IN4_Pin|DI_IN5_Pin|DI_IN6_Pin;
  GPIO_InitStruct.Mode = GPIO_MODE_INPUT;
  GPIO_InitStruct.Pull = GPIO_NOPULL;
  HAL_GPIO_Init(GPIOB, &GPIO_InitStruct);

  /*Configure GPIO pin : FAULT_Pin */
  GPIO_InitStruct.Pin = FAULT_Pin;
  GPIO_InitStruct.Mode = GPIO_MODE_OUTPUT_PP;
  GPIO_InitStruct.Pull = GPIO_PULLDOWN;
  GPIO_InitStruct.Speed = GPIO_SPEED_FREQ_LOW;
  HAL_GPIO_Init(FAULT_GPIO_Port, &GPIO_InitStruct);

  /*Configure GPIO pin : LCD_CLK_Pin */
  GPIO_InitStruct.Pin = LCD_CLK_Pin;
  GPIO_InitStruct.Mode = GPIO_MODE_OUTPUT_PP;
  GPIO_InitStruct.Pull = GPIO_PULLUP;
  GPIO_InitStruct.Speed = GPIO_SPEED_FREQ_LOW;
  HAL_GPIO_Init(LCD_CLK_GPIO_Port, &GPIO_InitStruct);

  /*Configure GPIO pin : MHU_Pin */
  GPIO_InitStruct.Pin = MHU_Pin;
  GPIO_InitStruct.Mode = GPIO_MODE_IT_RISING_FALLING;
  GPIO_InitStruct.Pull = GPIO_PULLUP;
  HAL_GPIO_Init(MHU_GPIO_Port, &GPIO_InitStruct);

  /*Configure GPIO pin : DI_IN0_Pin */
  GPIO_InitStruct.Pin = DI_IN0_Pin;
  GPIO_InitStruct.Mode = GPIO_MODE_IT_FALLING;
  GPIO_InitStruct.Pull = GPIO_NOPULL;
  HAL_GPIO_Init(DI_IN0_GPIO_Port, &GPIO_InitStruct);

  /*Configure GPIO pins : DI_IN2_Pin KEYSW_Pin */
  GPIO_InitStruct.Pin = DI_IN2_Pin|KEYSW_Pin;
  GPIO_InitStruct.Mode = GPIO_MODE_INPUT;
  GPIO_InitStruct.Pull = GPIO_NOPULL;
  HAL_GPIO_Init(GPIOA, &GPIO_InitStruct);

  /*Configure GPIO pin : MHW_Pin */
  GPIO_InitStruct.Pin = MHW_Pin;
  GPIO_InitStruct.Mode = GPIO_MODE_IT_RISING_FALLING;
  GPIO_InitStruct.Pull = GPIO_PULLUP;
  HAL_GPIO_Init(MHW_GPIO_Port, &GPIO_InitStruct);

  /*Configure GPIO pin : LATCH_AO_Pin */
  GPIO_InitStruct.Pin = LATCH_AO_Pin;
  GPIO_InitStruct.Mode = GPIO_MODE_OUTPUT_PP;
  GPIO_InitStruct.Pull = GPIO_NOPULL;
  GPIO_InitStruct.Speed = GPIO_SPEED_FREQ_LOW;
  HAL_GPIO_Init(LATCH_AO_GPIO_Port, &GPIO_InitStruct);

  /*Configure GPIO pins : MCU_WL_Pin MCU_VL_Pin MCU_UL_Pin */
  GPIO_InitStruct.Pin = MCU_WL_Pin|MCU_VL_Pin|MCU_UL_Pin;
  GPIO_InitStruct.Mode = GPIO_MODE_OUTPUT_PP;
  GPIO_InitStruct.Pull = GPIO_PULLDOWN;
  GPIO_InitStruct.Speed = GPIO_SPEED_FREQ_MEDIUM;
  HAL_GPIO_Init(GPIOB, &GPIO_InitStruct);

  /* EXTI interrupt init*/
  HAL_NVIC_SetPriority(EXTI2_IRQn, 0, 0);
  HAL_NVIC_EnableIRQ(EXTI2_IRQn);

  HAL_NVIC_SetPriority(EXTI4_IRQn, 0, 0);
  HAL_NVIC_EnableIRQ(EXTI4_IRQn);

  HAL_NVIC_SetPriority(EXTI9_5_IRQn, 0, 0);
  HAL_NVIC_EnableIRQ(EXTI9_5_IRQn);

}

void Error_Handler(void)
{
  __disable_irq();
  while (1)
  {
  }
}
